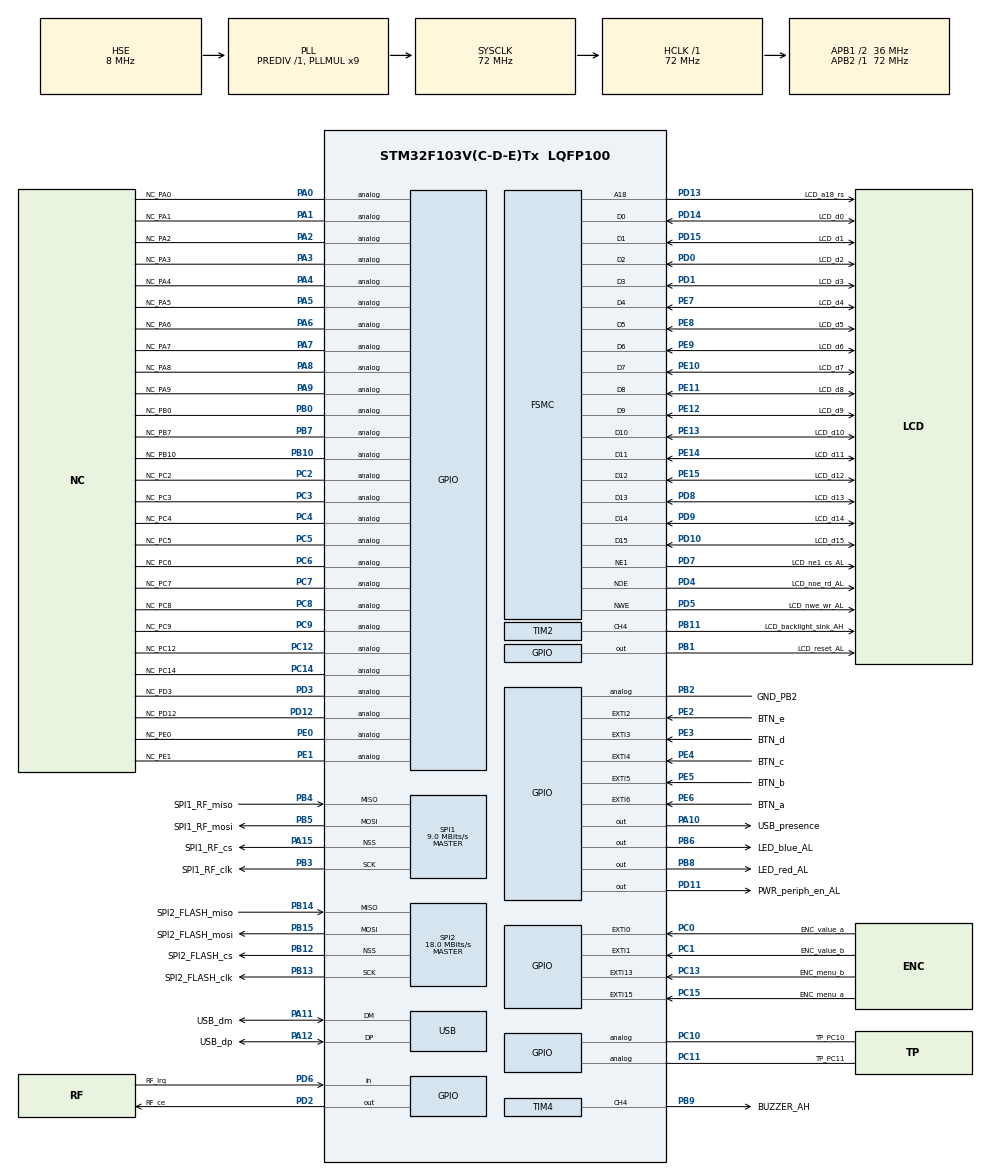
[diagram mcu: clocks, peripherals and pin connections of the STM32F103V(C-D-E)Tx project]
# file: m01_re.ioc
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FSMC.AddressSetupTime1=3
FSMC.BusTurnAroundDuration1=2
FSMC.DataSetupTime1=2
FSMC.ExtendedMode1=FSMC_EXTENDED_MODE_DISABLE
Mcu.Family=STM32F1
Mcu.Name=STM32F103V(C-D-E)Tx
Mcu.Package=LQFP100
NVIC.EXTI0_IRQn=true\:0\:0\:false\:true\:true\:1\:true\:true\:true
NVIC.EXTI15_10_IRQn=true\:0\:0\:false\:true\:true\:7\:true\:true\:true
NVIC.EXTI1_IRQn=true\:0\:0\:false\:true\:true\:2\:true\:true\:true
NVIC.EXTI2_IRQn=true\:0\:0\:false\:true\:true\:3\:true\:true\:true
NVIC.EXTI3_IRQn=true\:0\:0\:false\:true\:true\:4\:true\:true\:true
NVIC.EXTI4_IRQn=true\:0\:0\:false\:true\:true\:5\:true\:true\:true
NVIC.EXTI9_5_IRQn=true\:0\:0\:false\:true\:true\:6\:true\:true\:true
NVIC.PriorityGroup=NVIC_PRIORITYGROUP_4
NVIC.TIM6_IRQn=true\:0\:0\:false\:true\:true\:8\:true\:true\:true
OSC_IN.Mode=HSE-External-Oscillator
OSC_IN.Signal=RCC_OSC_IN
OSC_OUT.Mode=HSE-External-Oscillator
OSC_OUT.Signal=RCC_OSC_OUT
PA0-WKUP.GPIO_Label=NC_PA0
PA0-WKUP.Signal=GPIO_Analog
PA1.GPIO_Label=NC_PA1
PA1.Signal=GPIO_Analog
PA10.GPIO_Label=USB_presence
PA10.Signal=GPIO_Output
PA11.GPIO_Label=USB_dm
PA11.Mode=Device
PA11.Signal=USB_DM
PA12.GPIO_Label=USB_dp
PA12.Mode=Device
PA12.Signal=USB_DP
PA13.GPIO_Label=SWD_dio
PA13.Mode=Serial_Wire
PA13.Signal=SYS_JTMS-SWDIO
PA14.GPIO_Label=SWD_clk
PA14.Mode=Serial_Wire
PA14.Signal=SYS_JTCK-SWCLK
PA15.GPIO_Label=SPI1_RF_cs
PA15.Mode=NSS_Signal_Hard_Output
PA15.Signal=SPI1_NSS
PA2.GPIO_Label=NC_PA2
PA2.Signal=GPIO_Analog
PA3.GPIO_Label=NC_PA3
PA3.Signal=GPIO_Analog
PA4.GPIO_Label=NC_PA4
PA4.Signal=GPIO_Analog
PA5.GPIO_Label=NC_PA5
PA5.Signal=GPIO_Analog
PA6.GPIO_Label=NC_PA6
PA6.Signal=GPIO_Analog
PA7.GPIO_Label=NC_PA7
PA7.Signal=GPIO_Analog
PA8.GPIO_Label=NC_PA8
PA8.Signal=GPIO_Analog
PA9.GPIO_Label=NC_PA9
PA9.Signal=GPIO_Analog
PB0.GPIO_Label=NC_PB0
PB0.Signal=GPIO_Analog
PB1.GPIO_Label=LCD_reset_AL
PB1.PinState=GPIO_PIN_SET
PB1.Signal=GPIO_Output
PB10.GPIO_Label=NC_PB10
PB10.Signal=GPIO_Analog
PB11.GPIO_Label=LCD_backlight_sink_AH
PB11.GPIO_Speed=GPIO_SPEED_FREQ_LOW
PB11.Signal=S_TIM2_CH4
PB12.GPIO_Label=SPI2_FLASH_cs
PB12.Mode=NSS_Signal_Hard_Output
PB12.Signal=SPI2_NSS
PB13.GPIO_Label=SPI2_FLASH_clk
PB13.Mode=Full_Duplex_Master
PB13.Signal=SPI2_SCK
PB14.GPIO_Label=SPI2_FLASH_miso
PB14.Mode=Full_Duplex_Master
PB14.Signal=SPI2_MISO
PB15.GPIO_Label=SPI2_FLASH_mosi
PB15.Mode=Full_Duplex_Master
PB15.Signal=SPI2_MOSI
PB2.GPIO_Label=GND_PB2
PB2.Signal=GPIO_Analog
PB3.GPIO_Label=SPI1_RF_clk
PB3.Mode=Full_Duplex_Master
PB3.Signal=SPI1_SCK
PB4.GPIO_Label=SPI1_RF_miso
PB4.Mode=Full_Duplex_Master
PB4.Signal=SPI1_MISO
PB5.GPIO_Label=SPI1_RF_mosi
PB5.Mode=Full_Duplex_Master
PB5.Signal=SPI1_MOSI
PB6.GPIO_Label=LED_blue_AL
PB6.GPIO_ModeDefaultOutputPP=GPIO_MODE_OUTPUT_OD
PB6.GPIO_PuPd=GPIO_NOPULL
PB6.PinState=GPIO_PIN_SET
PB6.Signal=GPIO_Output
PB7.GPIO_Label=NC_PB7
PB7.Signal=GPIO_Analog
PB8.GPIO_Label=LED_red_AL
PB8.GPIO_ModeDefaultOutputPP=GPIO_MODE_OUTPUT_OD
PB8.GPIO_PuPd=GPIO_NOPULL
PB8.PinState=GPIO_PIN_SET
PB8.Signal=GPIO_Output
PB9.GPIO_Label=BUZZER_AH
PB9.Signal=S_TIM4_CH4
PC0.GPIO_Label=ENC_value_a
PC0.GPIO_ModeDefaultEXTI=GPIO_MODE_IT_RISING_FALLING
PC0.Signal=GPXTI0
PC1.GPIO_Label=ENC_value_b
PC1.GPIO_ModeDefaultEXTI=GPIO_MODE_IT_RISING_FALLING
PC1.Signal=GPXTI1
PC10.GPIO_Label=TP_PC10
PC10.Signal=GPIO_Analog
PC11.GPIO_Label=TP_PC11
PC11.Signal=GPIO_Analog
PC12.GPIO_Label=NC_PC12
PC12.Signal=GPIO_Analog
PC13-TAMPER-RTC.GPIO_Label=ENC_menu_b
PC13-TAMPER-RTC.GPIO_ModeDefaultEXTI=GPIO_MODE_IT_RISING_FALLING
PC13-TAMPER-RTC.Signal=GPXTI13
PC14-OSC32_IN.GPIO_Label=NC_PC14
PC14-OSC32_IN.Signal=GPIO_Analog
PC15-OSC32_OUT.GPIO_Label=ENC_menu_a
PC15-OSC32_OUT.GPIO_ModeDefaultEXTI=GPIO_MODE_IT_RISING_FALLING
PC15-OSC32_OUT.Signal=GPXTI15
PC2.GPIO_Label=NC_PC2
PC2.Signal=GPIO_Analog
PC3.GPIO_Label=NC_PC3
PC3.Signal=GPIO_Analog
PC4.GPIO_Label=NC_PC4
PC4.Signal=GPIO_Analog
PC5.GPIO_Label=NC_PC5
PC5.Signal=GPIO_Analog
PC6.GPIO_Label=NC_PC6
PC6.Signal=GPIO_Analog
PC7.GPIO_Label=NC_PC7
PC7.Signal=GPIO_Analog
PC8.GPIO_Label=NC_PC8
PC8.Signal=GPIO_Analog
PC9.GPIO_Label=NC_PC9
PC9.Signal=GPIO_Analog
PD0.GPIO_Label=LCD_d2
PD0.Mode=16b-d1
PD0.Signal=FSMC_D2
PD1.GPIO_Label=LCD_d3
PD1.Mode=16b-d1
PD1.Signal=FSMC_D3
PD10.GPIO_Label=LCD_d15
PD10.Mode=16b-d1
PD10.Signal=FSMC_D15
PD11.GPIO_Label=PWR_periph_en_AL
PD11.GPIO_ModeDefaultOutputPP=GPIO_MODE_OUTPUT_OD
PD11.GPIO_PuPd=GPIO_NOPULL
PD11.PinState=GPIO_PIN_RESET
PD11.Signal=GPIO_Output
PD12.GPIO_Label=NC_PD12
PD12.Signal=GPIO_Analog
PD13.GPIO_Label=LCD_a18_rs
PD13.Mode=A18_1
PD13.Signal=FSMC_A18
PD14.GPIO_Label=LCD_d0
PD14.Mode=16b-d1
PD14.Signal=FSMC_D0
PD15.GPIO_Label=LCD_d1
PD15.Mode=16b-d1
PD15.Signal=FSMC_D1
PD2.GPIO_Label=RF_ce
PD2.Signal=GPIO_Output
PD3.GPIO_Label=NC_PD3
PD3.Signal=GPIO_Analog
PD4.GPIO_Label=LCD_noe_rd_AL
PD4.Mode=Lcd1
PD4.Signal=FSMC_NOE
PD5.GPIO_Label=LCD_nwe_wr_AL
PD5.Mode=Lcd1
PD5.Signal=FSMC_NWE
PD6.GPIO_Label=RF_irq
PD6.Signal=GPIO_Input
PD7.GPIO_Label=LCD_ne1_cs_AL
PD7.Mode=NorPsramChipSelect1_1
PD7.Signal=FSMC_NE1
PD8.GPIO_Label=LCD_d13
PD8.Mode=16b-d1
PD8.Signal=FSMC_D13
PD9.GPIO_Label=LCD_d14
PD9.Mode=16b-d1
PD9.Signal=FSMC_D14
PE0.GPIO_Label=NC_PE0
PE0.Signal=GPIO_Analog
PE1.GPIO_Label=NC_PE1
PE1.Signal=GPIO_Analog
PE10.GPIO_Label=LCD_d7
PE10.Mode=16b-d1
PE10.Signal=FSMC_D7
PE11.GPIO_Label=LCD_d8
PE11.Mode=16b-d1
PE11.Signal=FSMC_D8
PE12.GPIO_Label=LCD_d9
PE12.Mode=16b-d1
PE12.Signal=FSMC_D9
PE13.GPIO_Label=LCD_d10
PE13.Mode=16b-d1
PE13.Signal=FSMC_D10
PE14.GPIO_Label=LCD_d11
PE14.Mode=16b-d1
PE14.Signal=FSMC_D11
PE15.GPIO_Label=LCD_d12
PE15.Mode=16b-d1
PE15.Signal=FSMC_D12
PE2.GPIO_Label=BTN_e
PE2.GPIO_ModeDefaultEXTI=GPIO_MODE_IT_RISING_FALLING
PE2.GPIO_PuPd=GPIO_PULLUP
PE2.Signal=GPXTI2
PE3.GPIO_Label=BTN_d
PE3.GPIO_ModeDefaultEXTI=GPIO_MODE_IT_RISING_FALLING
PE3.GPIO_PuPd=GPIO_PULLUP
PE3.Signal=GPXTI3
PE4.GPIO_Label=BTN_c
PE4.GPIO_ModeDefaultEXTI=GPIO_MODE_IT_RISING_FALLING
PE4.GPIO_PuPd=GPIO_PULLUP
PE4.Signal=GPXTI4
PE5.GPIO_Label=BTN_b
PE5.GPIO_ModeDefaultEXTI=GPIO_MODE_IT_RISING_FALLING
PE5.GPIO_PuPd=GPIO_PULLUP
PE5.Signal=GPXTI5
PE6.GPIO_Label=BTN_a
PE6.GPIO_ModeDefaultEXTI=GPIO_MODE_IT_RISING_FALLING
PE6.GPIO_PuPd=GPIO_PULLUP
PE6.Signal=GPXTI6
PE7.GPIO_Label=LCD_d4
PE7.Mode=16b-d1
PE7.Signal=FSMC_D4
PE8.GPIO_Label=LCD_d5
PE8.Mode=16b-d1
PE8.Signal=FSMC_D5
PE9.GPIO_Label=LCD_d6
PE9.Mode=16b-d1
PE9.Signal=FSMC_D6
ProjectManager.HeapSize=0x200
ProjectManager.StackSize=0x400
ProjectManager.TargetToolchain=STM32CubeIDE
RCC.AHBFreq_Value=72000000
RCC.APB1CLKDivider=RCC_HCLK_DIV2
RCC.APB1Freq_Value=36000000
RCC.APB1TimFreq_Value=72000000
RCC.APB2Freq_Value=72000000
RCC.APB2TimFreq_Value=72000000
RCC.EnbaleCSS=true
RCC.HCLKFreq_Value=72000000
RCC.PLLMUL=RCC_PLL_MUL9
RCC.SYSCLKFreq_VALUE=72000000
RCC.SYSCLKSource=RCC_SYSCLKSOURCE_PLLCLK
RCC.USBFreq_Value=48000000
RCC.USBPrescaler=RCC_USBCLKSOURCE_PLL_DIV1_5
SH.S_TIM2_CH4.0=TIM2_CH4,PWM Generation4 CH4
SH.S_TIM4_CH4.0=TIM4_CH4,PWM Generation4 CH4
SPI1.BaudRatePrescaler=SPI_BAUDRATEPRESCALER_8
SPI1.CalculateBaudRate=9.0 MBits/s
SPI1.Direction=SPI_DIRECTION_2LINES
SPI1.Mode=SPI_MODE_MASTER
SPI1.VirtualNSS=VM_NSSHARD
SPI1.VirtualType=VM_MASTER
SPI2.CalculateBaudRate=18.0 MBits/s
SPI2.Direction=SPI_DIRECTION_2LINES
SPI2.Mode=SPI_MODE_MASTER
SPI2.VirtualNSS=VM_NSSHARD
SPI2.VirtualType=VM_MASTER
TIM2.AutoReloadPreload=TIM_AUTORELOAD_PRELOAD_DISABLE
TIM2.Channel-PWM\ Generation4\ CH4=TIM_CHANNEL_4
TIM2.Period=100-1
TIM2.Prescaler=36
TIM4.Channel-PWM\ Generation4\ CH4=TIM_CHANNEL_4
TIM4.Period=300-1
TIM4.Prescaler=72
TIM4.Pulse-PWM\ Generation4\ CH4=150
TIM6.AutoReloadPreload=TIM_AUTORELOAD_PRELOAD_DISABLE
TIM6.Period=30000
TIM6.Prescaler=7200
TIM6.TIM_MasterOutputTrigger=TIM_TRGO_RESET
VP_TIM6_VS_ClockSourceINT.Mode=Enable_Timer
board=custom

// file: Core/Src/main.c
/* USER CODE BEGIN Header */
/**
  ******************************************************************************
  * @file           : main.c
  * @brief          : Main program body
  ******************************************************************************
  * @attention
  *
  * Copyright (c) 2024 STMicroelectronics.
  * All rights reserved.
  *
  * This software is licensed under terms that can be found in the LICENSE file
  * in the root directory of this software component.
  * If no LICENSE file comes with this software, it is provided AS-IS.
  *
  ******************************************************************************
  */
/* USER CODE END Header */
#include <stdbool.h>
#include "main.h"

/* USER CODE BEGIN Includes */
#include "stm32f1xx_hal.h"
/* USER CODE END Includes */

/* USER CODE BEGIN PD */
#define BTN_DEBOUNCE_MS 5
/* USER CODE END PD */

SPI_HandleTypeDef hspi1;
SPI_HandleTypeDef hspi2;

TIM_HandleTypeDef htim2;
TIM_HandleTypeDef htim4;
TIM_HandleTypeDef htim6;

PCD_HandleTypeDef hpcd_USB_FS;

SRAM_HandleTypeDef hsram1;

/* USER CODE BEGIN PV */
volatile uint32_t BTN_a_prev_edge_ms = 0;
volatile uint32_t BTN_b_prev_edge_ms = 0;
volatile uint32_t BTN_c_prev_edge_ms = 0;
volatile uint32_t BTN_d_prev_edge_ms = 0;
volatile uint32_t BTN_e_prev_edge_ms = 0;

volatile bool BUZZER_en = false;
volatile uint32_t LCD_backlight_percent = 100;
/* USER CODE END PV */

void SystemClock_Config(void);
static void MX_GPIO_Init(void);
static void MX_FSMC_Init(void);
static void MX_SPI2_Init(void);
static void MX_SPI1_Init(void);
static void MX_TIM2_Init(void);
static void MX_TIM4_Init(void);
static void MX_TIM6_Init(void);
static void MX_USB_PCD_Init(void);
static void MX_NVIC_Init(void);

/* USER CODE BEGIN 0 */

void HAL_GPIO_EXTI_Callback(uint16_t GPIO_Pin)
{
	switch (GPIO_Pin) {
		case BTN_a_Pin:
    {
      uint32_t state = READ_BIT(BTN_a_GPIO_Port->IDR, BTN_a_Pin);

      if (HAL_GetTick() - BTN_a_prev_edge_ms < BTN_DEBOUNCE_MS) {
        break;
      }

      BTN_a_prev_edge_ms = HAL_GetTick();
      if (!state) {
        //pressed
        HAL_GPIO_TogglePin(LED_red_AL_GPIO_Port, LED_red_AL_Pin);
      } else {
        //released
      }

      break;
    }
		case BTN_b_Pin:
		{
			uint32_t state = READ_BIT(BTN_b_GPIO_Port->IDR, BTN_b_Pin);

			if (HAL_GetTick() - BTN_b_prev_edge_ms < BTN_DEBOUNCE_MS) {
        break;
			}

			BTN_b_prev_edge_ms = HAL_GetTick();
			if (!state) {
				//pressed
        HAL_GPIO_TogglePin(LED_blue_AL_GPIO_Port, LED_blue_AL_Pin);
			} else {
				//released
			}

			break;
		}
		case BTN_c_Pin:
    {
      uint32_t state = READ_BIT(BTN_c_GPIO_Port->IDR, BTN_c_Pin);

      if (HAL_GetTick() - BTN_c_prev_edge_ms < BTN_DEBOUNCE_MS) {
        break;
      }

      BTN_c_prev_edge_ms = HAL_GetTick();
      if (!state) {
        //pressed
        if (BUZZER_en) {
          HAL_TIM_PWM_Stop(&htim4, TIM_CHANNEL_4);
          BUZZER_en = false;
        } else {
          HAL_TIM_PWM_Start(&htim4, TIM_CHANNEL_4);
          BUZZER_en = true;
        }
      } else {
        //released
      }

      break;
    }
		case BTN_d_Pin:
    {
      uint32_t state = READ_BIT(BTN_d_GPIO_Port->IDR, BTN_d_Pin);

      if (HAL_GetTick() - BTN_d_prev_edge_ms < BTN_DEBOUNCE_MS) {
        break;
      }

      BTN_d_prev_edge_ms = HAL_GetTick();
      if (!state) {
        //pressed
        if (LCD_backlight_percent >= 10) {
          LCD_backlight_percent -= 10;
        }
      } else {
        //released
      }

      htim2.Instance->CCR4 = LCD_backlight_percent;

      break;
    }
		case BTN_e_Pin:
    {
      uint32_t state = READ_BIT(BTN_e_GPIO_Port->IDR, BTN_e_Pin);

      if (HAL_GetTick() - BTN_e_prev_edge_ms < BTN_DEBOUNCE_MS) {
        break;
      }

      BTN_e_prev_edge_ms = HAL_GetTick();
      if (!state) {
        //pressed
        if (LCD_backlight_percent < 100) {
          LCD_backlight_percent += 10;
        }
      } else {
        //released
      }

      htim2.Instance->CCR4 = LCD_backlight_percent;

      break;
    }
		case ENC_menu_a_Pin:
      break;
		case ENC_menu_b_Pin:
      break;
    case ENC_value_a_Pin:
      break;
    case ENC_value_b_Pin:
      break;
		default:
			break;
	}

}

void HAL_TIM_PeriodElapsedCallback(TIM_HandleTypeDef *htim)
{
  switch ((uint32_t)htim->Instance) {
    case TIM6_BASE:
      HAL_GPIO_TogglePin(LED_blue_AL_GPIO_Port, LED_blue_AL_Pin);
      break;

    default:
      break;

  }
}
/* USER CODE END 0 */

int main(void)
{

  /* MCU Configuration--------------------------------------------------------*/

  /* Reset of all peripherals, Initializes the Flash interface and the Systick. */
  HAL_Init();

  /* Configure the system clock */
  SystemClock_Config();

  /* Initialize all configured peripherals */
  MX_GPIO_Init();
  MX_FSMC_Init();
  MX_SPI2_Init();
  MX_SPI1_Init();
  MX_TIM2_Init();
  MX_TIM4_Init();
  MX_TIM6_Init();
  MX_USB_PCD_Init();

  /* Initialize interrupts */
  MX_NVIC_Init();
  /* USER CODE BEGIN 2 */

  // start LCD backlight PWM; CCR4 0 = off ; CCR4 100 = HIGH
  HAL_TIM_PWM_Start(&htim2, TIM_CHANNEL_4);
  htim2.Instance->CCR4 = 0;

  // enable peripheral power (has no effect on v1.3)
  HAL_GPIO_WritePin(PWR_periph_en_AL_GPIO_Port, PWR_periph_en_AL_Pin, GPIO_PIN_RESET);
  HAL_Delay(100);

  // set LCD backlight
  htim2.Instance->CCR4 = LCD_backlight_percent;

  /* USER CODE END 2 */

  /* Infinite loop */
  while (1)
  {

  }
}

void SystemClock_Config(void)
{
  RCC_OscInitTypeDef RCC_OscInitStruct = {0};
  RCC_ClkInitTypeDef RCC_ClkInitStruct = {0};
  RCC_PeriphCLKInitTypeDef PeriphClkInit = {0};

  /** Initializes the RCC Oscillators according to the specified parameters
  * in the RCC_OscInitTypeDef structure.
  */
  RCC_OscInitStruct.OscillatorType = RCC_OSCILLATORTYPE_HSE;
  RCC_OscInitStruct.HSEState = RCC_HSE_ON;
  RCC_OscInitStruct.HSEPredivValue = RCC_HSE_PREDIV_DIV1;
  RCC_OscInitStruct.HSIState = RCC_HSI_ON;
  RCC_OscInitStruct.PLL.PLLState = RCC_PLL_ON;
  RCC_OscInitStruct.PLL.PLLSource = RCC_PLLSOURCE_HSE;
  RCC_OscInitStruct.PLL.PLLMUL = RCC_PLL_MUL9;
  if (HAL_RCC_OscConfig(&RCC_OscInitStruct) != HAL_OK)
  {
    Error_Handler();
  }

  /** Initializes the CPU, AHB and APB buses clocks
  */
  RCC_ClkInitStruct.ClockType = RCC_CLOCKTYPE_HCLK|RCC_CLOCKTYPE_SYSCLK
                              |RCC_CLOCKTYPE_PCLK1|RCC_CLOCKTYPE_PCLK2;
  RCC_ClkInitStruct.SYSCLKSource = RCC_SYSCLKSOURCE_PLLCLK;
  RCC_ClkInitStruct.AHBCLKDivider = RCC_SYSCLK_DIV1;
  RCC_ClkInitStruct.APB1CLKDivider = RCC_HCLK_DIV2;
  RCC_ClkInitStruct.APB2CLKDivider = RCC_HCLK_DIV1;

  if (HAL_RCC_ClockConfig(&RCC_ClkInitStruct, FLASH_LATENCY_2) != HAL_OK)
  {
    Error_Handler();
  }
  PeriphClkInit.PeriphClockSelection = RCC_PERIPHCLK_USB;
  PeriphClkInit.UsbClockSelection = RCC_USBCLKSOURCE_PLL_DIV1_5;
  if (HAL_RCCEx_PeriphCLKConfig(&PeriphClkInit) != HAL_OK)
  {
    Error_Handler();
  }

  /** Enables the Clock Security System
  */
  HAL_RCC_EnableCSS();
}

/**
  * @brief NVIC Configuration.
  * @retval None
  */
static void MX_NVIC_Init(void)
{
  /* EXTI0_IRQn interrupt configuration */
  HAL_NVIC_SetPriority(EXTI0_IRQn, 0, 0);
  HAL_NVIC_EnableIRQ(EXTI0_IRQn);
  /* EXTI1_IRQn interrupt configuration */
  HAL_NVIC_SetPriority(EXTI1_IRQn, 0, 0);
  HAL_NVIC_EnableIRQ(EXTI1_IRQn);
  /* EXTI2_IRQn interrupt configuration */
  HAL_NVIC_SetPriority(EXTI2_IRQn, 0, 0);
  HAL_NVIC_EnableIRQ(EXTI2_IRQn);
  /* EXTI3_IRQn interrupt configuration */
  HAL_NVIC_SetPriority(EXTI3_IRQn, 0, 0);
  HAL_NVIC_EnableIRQ(EXTI3_IRQn);
  /* EXTI4_IRQn interrupt configuration */
  HAL_NVIC_SetPriority(EXTI4_IRQn, 0, 0);
  HAL_NVIC_EnableIRQ(EXTI4_IRQn);
  /* EXTI9_5_IRQn interrupt configuration */
  HAL_NVIC_SetPriority(EXTI9_5_IRQn, 0, 0);
  HAL_NVIC_EnableIRQ(EXTI9_5_IRQn);
  /* EXTI15_10_IRQn interrupt configuration */
  HAL_NVIC_SetPriority(EXTI15_10_IRQn, 0, 0);
  HAL_NVIC_EnableIRQ(EXTI15_10_IRQn);
  /* TIM6_IRQn interrupt configuration */
  HAL_NVIC_SetPriority(TIM6_IRQn, 0, 0);
  HAL_NVIC_EnableIRQ(TIM6_IRQn);
}

static void MX_SPI1_Init(void)
{

  /* SPI1 parameter configuration*/
  hspi1.Instance = SPI1;
  hspi1.Init.Mode = SPI_MODE_MASTER;
  hspi1.Init.Direction = SPI_DIRECTION_2LINES;
  hspi1.Init.DataSize = SPI_DATASIZE_8BIT;
  hspi1.Init.CLKPolarity = SPI_POLARITY_LOW;
  hspi1.Init.CLKPhase = SPI_PHASE_1EDGE;
  hspi1.Init.NSS = SPI_NSS_HARD_OUTPUT;
  hspi1.Init.BaudRatePrescaler = SPI_BAUDRATEPRESCALER_8;
  hspi1.Init.FirstBit = SPI_FIRSTBIT_MSB;
  hspi1.Init.TIMode = SPI_TIMODE_DISABLE;
  hspi1.Init.CRCCalculation = SPI_CRCCALCULATION_DISABLE;
  hspi1.Init.CRCPolynomial = 10;
  if (HAL_SPI_Init(&hspi1) != HAL_OK)
  {
    Error_Handler();
  }

}

static void MX_SPI2_Init(void)
{

  /* SPI2 parameter configuration*/
  hspi2.Instance = SPI2;
  hspi2.Init.Mode = SPI_MODE_MASTER;
  hspi2.Init.Direction = SPI_DIRECTION_2LINES;
  hspi2.Init.DataSize = SPI_DATASIZE_8BIT;
  hspi2.Init.CLKPolarity = SPI_POLARITY_LOW;
  hspi2.Init.CLKPhase = SPI_PHASE_1EDGE;
  hspi2.Init.NSS = SPI_NSS_HARD_OUTPUT;
  hspi2.Init.BaudRatePrescaler = SPI_BAUDRATEPRESCALER_2;
  hspi2.Init.FirstBit = SPI_FIRSTBIT_MSB;
  hspi2.Init.TIMode = SPI_TIMODE_DISABLE;
  hspi2.Init.CRCCalculation = SPI_CRCCALCULATION_DISABLE;
  hspi2.Init.CRCPolynomial = 10;
  if (HAL_SPI_Init(&hspi2) != HAL_OK)
  {
    Error_Handler();
  }

}

static void MX_TIM2_Init(void)
{

  TIM_MasterConfigTypeDef sMasterConfig = {0};
  TIM_OC_InitTypeDef sConfigOC = {0};

  htim2.Instance = TIM2;
  htim2.Init.Prescaler = 36;
  htim2.Init.CounterMode = TIM_COUNTERMODE_UP;
  htim2.Init.Period = 100-1;
  htim2.Init.ClockDivision = TIM_CLOCKDIVISION_DIV1;
  htim2.Init.AutoReloadPreload = TIM_AUTORELOAD_PRELOAD_DISABLE;
  if (HAL_TIM_PWM_Init(&htim2) != HAL_OK)
  {
    Error_Handler();
  }
  sMasterConfig.MasterOutputTrigger = TIM_TRGO_RESET;
  sMasterConfig.MasterSlaveMode = TIM_MASTERSLAVEMODE_DISABLE;
  if (HAL_TIMEx_MasterConfigSynchronization(&htim2, &sMasterConfig) != HAL_OK)
  {
    Error_Handler();
  }
  sConfigOC.OCMode = TIM_OCMODE_PWM1;
  sConfigOC.Pulse = 0;
  sConfigOC.OCPolarity = TIM_OCPOLARITY_HIGH;
  sConfigOC.OCFastMode = TIM_OCFAST_DISABLE;
  if (HAL_TIM_PWM_ConfigChannel(&htim2, &sConfigOC, TIM_CHANNEL_4) != HAL_OK)
  {
    Error_Handler();
  }
  HAL_TIM_MspPostInit(&htim2);

}

static void MX_TIM4_Init(void)
{

  TIM_MasterConfigTypeDef sMasterConfig = {0};
  TIM_OC_InitTypeDef sConfigOC = {0};

  htim4.Instance = TIM4;
  htim4.Init.Prescaler = 72;
  htim4.Init.CounterMode = TIM_COUNTERMODE_UP;
  htim4.Init.Period = 300-1;
  htim4.Init.ClockDivision = TIM_CLOCKDIVISION_DIV1;
  htim4.Init.AutoReloadPreload = TIM_AUTORELOAD_PRELOAD_DISABLE;
  if (HAL_TIM_PWM_Init(&htim4) != HAL_OK)
  {
    Error_Handler();
  }
  sMasterConfig.MasterOutputTrigger = TIM_TRGO_RESET;
  sMasterConfig.MasterSlaveMode = TIM_MASTERSLAVEMODE_DISABLE;
  if (HAL_TIMEx_MasterConfigSynchronization(&htim4, &sMasterConfig) != HAL_OK)
  {
    Error_Handler();
  }
  sConfigOC.OCMode = TIM_OCMODE_PWM1;
  sConfigOC.Pulse = 150;
  sConfigOC.OCPolarity = TIM_OCPOLARITY_HIGH;
  sConfigOC.OCFastMode = TIM_OCFAST_DISABLE;
  if (HAL_TIM_PWM_ConfigChannel(&htim4, &sConfigOC, TIM_CHANNEL_4) != HAL_OK)
  {
    Error_Handler();
  }
  HAL_TIM_MspPostInit(&htim4);

}

static void MX_TIM6_Init(void)
{

  TIM_MasterConfigTypeDef sMasterConfig = {0};

  htim6.Instance = TIM6;
  htim6.Init.Prescaler = 7200;
  htim6.Init.CounterMode = TIM_COUNTERMODE_UP;
  htim6.Init.Period = 30000;
  htim6.Init.AutoReloadPreload = TIM_AUTORELOAD_PRELOAD_DISABLE;
  if (HAL_TIM_Base_Init(&htim6) != HAL_OK)
  {
    Error_Handler();
  }
  sMasterConfig.MasterOutputTrigger = TIM_TRGO_RESET;
  sMasterConfig.MasterSlaveMode = TIM_MASTERSLAVEMODE_DISABLE;
  if (HAL_TIMEx_MasterConfigSynchronization(&htim6, &sMasterConfig) != HAL_OK)
  {
    Error_Handler();
  }
  /* USER CODE BEGIN TIM6_Init 2 */
  // enable interrupt on update
  SET_BIT(htim6.Instance->DIER, TIM_IT_UPDATE);

  /* USER CODE END TIM6_Init 2 */

}

static void MX_USB_PCD_Init(void)
{

  hpcd_USB_FS.Instance = USB;
  hpcd_USB_FS.Init.dev_endpoints = 8;
  hpcd_USB_FS.Init.speed = PCD_SPEED_FULL;
  hpcd_USB_FS.Init.low_power_enable = DISABLE;
  hpcd_USB_FS.Init.lpm_enable = DISABLE;
  hpcd_USB_FS.Init.battery_charging_enable = DISABLE;
  if (HAL_PCD_Init(&hpcd_USB_FS) != HAL_OK)
  {
    Error_Handler();
  }

}

static void MX_GPIO_Init(void)
{
  GPIO_InitTypeDef GPIO_InitStruct = {0};

  /* GPIO Ports Clock Enable */
  __HAL_RCC_GPIOE_CLK_ENABLE();
  __HAL_RCC_GPIOC_CLK_ENABLE();
  __HAL_RCC_GPIOA_CLK_ENABLE();
  __HAL_RCC_GPIOB_CLK_ENABLE();
  __HAL_RCC_GPIOD_CLK_ENABLE();

  /*Configure GPIO pin Output Level */
  HAL_GPIO_WritePin(GPIOB, LCD_reset_AL_Pin|LED_blue_AL_Pin|LED_red_AL_Pin, GPIO_PIN_SET);

  /*Configure GPIO pin Output Level */
  HAL_GPIO_WritePin(GPIOD, PWR_periph_en_AL_Pin|RF_ce_Pin, GPIO_PIN_RESET);

  /*Configure GPIO pin Output Level */
  HAL_GPIO_WritePin(USB_presence_GPIO_Port, USB_presence_Pin, GPIO_PIN_RESET);

  /*Configure GPIO pins : BTN_e_Pin BTN_d_Pin BTN_c_Pin BTN_b_Pin
                           BTN_a_Pin */
  GPIO_InitStruct.Pin = BTN_e_Pin|BTN_d_Pin|BTN_c_Pin|BTN_b_Pin
                          |BTN_a_Pin;
  GPIO_InitStruct.Mode = GPIO_MODE_IT_RISING_FALLING;
  GPIO_InitStruct.Pull = GPIO_PULLUP;
  HAL_GPIO_Init(GPIOE, &GPIO_InitStruct);

  /*Configure GPIO pins : ENC_menu_b_Pin ENC_menu_a_Pin ENC_value_a_Pin ENC_value_b_Pin */
  GPIO_InitStruct.Pin = ENC_menu_b_Pin|ENC_menu_a_Pin|ENC_value_a_Pin|ENC_value_b_Pin;
  GPIO_InitStruct.Mode = GPIO_MODE_IT_RISING_FALLING;
  GPIO_InitStruct.Pull = GPIO_NOPULL;
  HAL_GPIO_Init(GPIOC, &GPIO_InitStruct);

  /*Configure GPIO pins : NC_PC14_Pin NC_PC2_Pin NC_PC3_Pin NC_PC4_Pin
                           NC_PC5_Pin NC_PC6_Pin NC_PC7_Pin NC_PC8_Pin
                           NC_PC9_Pin TP_PC10_Pin TP_PC11_Pin NC_PC12_Pin */
  GPIO_InitStruct.Pin = NC_PC14_Pin|NC_PC2_Pin|NC_PC3_Pin|NC_PC4_Pin
                          |NC_PC5_Pin|NC_PC6_Pin|NC_PC7_Pin|NC_PC8_Pin
                          |NC_PC9_Pin|TP_PC10_Pin|TP_PC11_Pin|NC_PC12_Pin;
  GPIO_InitStruct.Mode = GPIO_MODE_ANALOG;
  HAL_GPIO_Init(GPIOC, &GPIO_InitStruct);

  /*Configure GPIO pins : NC_PA0_Pin NC_PA1_Pin NC_PA2_Pin NC_PA3_Pin
                           NC_PA4_Pin NC_PA5_Pin NC_PA6_Pin NC_PA7_Pin
                           NC_PA8_Pin NC_PA9_Pin */
  GPIO_InitStruct.Pin = NC_PA0_Pin|NC_PA1_Pin|NC_PA2_Pin|NC_PA3_Pin
                          |NC_PA4_Pin|NC_PA5_Pin|NC_PA6_Pin|NC_PA7_Pin
                          |NC_PA8_Pin|NC_PA9_Pin;
  GPIO_InitStruct.Mode = GPIO_MODE_ANALOG;
  HAL_GPIO_Init(GPIOA, &GPIO_InitStruct);

  /*Configure GPIO pins : NC_PB0_Pin GND_PB2_Pin NC_PB10_Pin NC_PB7_Pin */
  GPIO_InitStruct.Pin = NC_PB0_Pin|GND_PB2_Pin|NC_PB10_Pin|NC_PB7_Pin;
  GPIO_InitStruct.Mode = GPIO_MODE_ANALOG;
  HAL_GPIO_Init(GPIOB, &GPIO_InitStruct);

  /*Configure GPIO pin : LCD_reset_AL_Pin */
  GPIO_InitStruct.Pin = LCD_reset_AL_Pin;
  GPIO_InitStruct.Mode = GPIO_MODE_OUTPUT_PP;
  GPIO_InitStruct.Pull = GPIO_NOPULL;
  GPIO_InitStruct.Speed = GPIO_SPEED_FREQ_LOW;
  HAL_GPIO_Init(LCD_reset_AL_GPIO_Port, &GPIO_InitStruct);

  /*Configure GPIO pin : PWR_periph_en_AL_Pin */
  GPIO_InitStruct.Pin = PWR_periph_en_AL_Pin;
  GPIO_InitStruct.Mode = GPIO_MODE_OUTPUT_OD;
  GPIO_InitStruct.Pull = GPIO_NOPULL;
  GPIO_InitStruct.Speed = GPIO_SPEED_FREQ_LOW;
  HAL_GPIO_Init(PWR_periph_en_AL_GPIO_Port, &GPIO_InitStruct);

  /*Configure GPIO pins : NC_PD12_Pin NC_PD3_Pin */
  GPIO_InitStruct.Pin = NC_PD12_Pin|NC_PD3_Pin;
  GPIO_InitStruct.Mode = GPIO_MODE_ANALOG;
  HAL_GPIO_Init(GPIOD, &GPIO_InitStruct);

  /*Configure GPIO pin : USB_presence_Pin */
  GPIO_InitStruct.Pin = USB_presence_Pin;
  GPIO_InitStruct.Mode = GPIO_MODE_OUTPUT_PP;
  GPIO_InitStruct.Pull = GPIO_NOPULL;
  GPIO_InitStruct.Speed = GPIO_SPEED_FREQ_LOW;
  HAL_GPIO_Init(USB_presence_GPIO_Port, &GPIO_InitStruct);

  /*Configure GPIO pin : RF_ce_Pin */
  GPIO_InitStruct.Pin = RF_ce_Pin;
  GPIO_InitStruct.Mode = GPIO_MODE_OUTPUT_PP;
  GPIO_InitStruct.Pull = GPIO_NOPULL;
  GPIO_InitStruct.Speed = GPIO_SPEED_FREQ_LOW;
  HAL_GPIO_Init(RF_ce_GPIO_Port, &GPIO_InitStruct);

  /*Configure GPIO pin : RF_irq_Pin */
  GPIO_InitStruct.Pin = RF_irq_Pin;
  GPIO_InitStruct.Mode = GPIO_MODE_INPUT;
  GPIO_InitStruct.Pull = GPIO_NOPULL;
  HAL_GPIO_Init(RF_irq_GPIO_Port, &GPIO_InitStruct);

  /*Configure GPIO pins : LED_blue_AL_Pin LED_red_AL_Pin */
  GPIO_InitStruct.Pin = LED_blue_AL_Pin|LED_red_AL_Pin;
  GPIO_InitStruct.Mode = GPIO_MODE_OUTPUT_OD;
  GPIO_InitStruct.Pull = GPIO_NOPULL;
  GPIO_InitStruct.Speed = GPIO_SPEED_FREQ_LOW;
  HAL_GPIO_Init(GPIOB, &GPIO_InitStruct);

  /*Configure GPIO pins : NC_PE0_Pin NC_PE1_Pin */
  GPIO_InitStruct.Pin = NC_PE0_Pin|NC_PE1_Pin;
  GPIO_InitStruct.Mode = GPIO_MODE_ANALOG;
  HAL_GPIO_Init(GPIOE, &GPIO_InitStruct);

/* USER CODE BEGIN MX_GPIO_Init_2 */

  // enable internal pull downs for all NC pins,
  // except GND_PB2_Pin since it's already tied to gnd
  GPIO_InitStruct.Pin = NC_PC14_Pin|NC_PC2_Pin|NC_PC3_Pin|NC_PC4_Pin
                        |NC_PC5_Pin|NC_PC6_Pin|NC_PC7_Pin|NC_PC8_Pin
                        |NC_PC9_Pin|TP_PC10_Pin|TP_PC11_Pin|NC_PC12_Pin;
  GPIO_InitStruct.Mode = GPIO_MODE_ANALOG;
  GPIO_InitStruct.Pull = GPIO_PULLDOWN;
  HAL_GPIO_Init(GPIOC, &GPIO_InitStruct);

  GPIO_InitStruct.Pin = NC_PA0_Pin|NC_PA1_Pin|NC_PA2_Pin|NC_PA3_Pin
                        |NC_PA4_Pin|NC_PA5_Pin|NC_PA6_Pin|NC_PA7_Pin
                        |NC_PA8_Pin|NC_PA9_Pin;
  GPIO_InitStruct.Mode = GPIO_MODE_ANALOG;
  GPIO_InitStruct.Pull = GPIO_PULLDOWN;
  HAL_GPIO_Init(GPIOA, &GPIO_InitStruct);

  GPIO_InitStruct.Pin = NC_PB0_Pin|NC_PB10_Pin|NC_PB7_Pin;
  GPIO_InitStruct.Mode = GPIO_MODE_ANALOG;
  GPIO_InitStruct.Pull = GPIO_PULLDOWN;
  HAL_GPIO_Init(GPIOB, &GPIO_InitStruct);

/* USER CODE END MX_GPIO_Init_2 */
}

/* FSMC initialization function */
static void MX_FSMC_Init(void)
{

  FSMC_NORSRAM_TimingTypeDef Timing = {0};

  /** Perform the SRAM1 memory initialization sequence
  */
  hsram1.Instance = FSMC_NORSRAM_DEVICE;
  hsram1.Extended = FSMC_NORSRAM_EXTENDED_DEVICE;
  /* hsram1.Init */
  hsram1.Init.NSBank = FSMC_NORSRAM_BANK1;
  hsram1.Init.DataAddressMux = FSMC_DATA_ADDRESS_MUX_DISABLE;
  hsram1.Init.MemoryType = FSMC_MEMORY_TYPE_SRAM;
  hsram1.Init.MemoryDataWidth = FSMC_NORSRAM_MEM_BUS_WIDTH_16;
  hsram1.Init.BurstAccessMode = FSMC_BURST_ACCESS_MODE_DISABLE;
  hsram1.Init.WaitSignalPolarity = FSMC_WAIT_SIGNAL_POLARITY_LOW;
  hsram1.Init.WrapMode = FSMC_WRAP_MODE_DISABLE;
  hsram1.Init.WaitSignalActive = FSMC_WAIT_TIMING_BEFORE_WS;
  hsram1.Init.WriteOperation = FSMC_WRITE_OPERATION_ENABLE;
  hsram1.Init.WaitSignal = FSMC_WAIT_SIGNAL_DISABLE;
  hsram1.Init.ExtendedMode = FSMC_EXTENDED_MODE_DISABLE;
  hsram1.Init.AsynchronousWait = FSMC_ASYNCHRONOUS_WAIT_DISABLE;
  hsram1.Init.WriteBurst = FSMC_WRITE_BURST_DISABLE;
  /* Timing */
  Timing.AddressSetupTime = 3;
  Timing.AddressHoldTime = 15;
  Timing.DataSetupTime = 2;
  Timing.BusTurnAroundDuration = 2;
  Timing.CLKDivision = 16;
  Timing.DataLatency = 17;
  Timing.AccessMode = FSMC_ACCESS_MODE_A;
  /* ExtTiming */

  if (HAL_SRAM_Init(&hsram1, &Timing, NULL) != HAL_OK)
  {
    Error_Handler( );
  }

  /** Disconnect NADV
  */

  __HAL_AFIO_FSMCNADV_DISCONNECTED();

}

void Error_Handler(void)
{
  __disable_irq();
  while (1)
  {
  }
}
